AUTOSAR XML (schema 4-0-3)
package /CalibrationComponents
  parameter sw component type SOER: data-type-mapping=SOER_CodeDataTypeMappingsSet
    provide port SOER_Pport: provided-interface=SOER_if
      provided-com-specs:
        init-value=20.408000946044922, parameter=KeSOER_kE_BattRmngEnergy_MaxVal
        init-value=0, parameter=KeSOER_kE_BattRmngEnergy_minVal
        init-value=0, parameter=KeSOER_kE_OvrdValue_BattRmngEnergy
        init-value=0, parameter=KeSOER_b_OvrdCond_BattRmngEnergy
package /SOER_Code_pkg/SOER_Code_swc
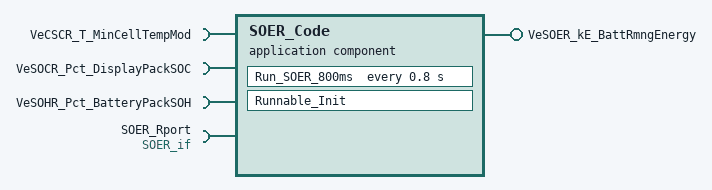
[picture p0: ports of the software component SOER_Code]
  application sw component type SOER_Code
    require port VeCSCR_T_MinCellTempMod: nonqueued-receiver-com-spec{data-element=VeCSCR_T_MinCellTempMod, init-value=0}, required-interface=VeCSCR_T_MinCellTempMod
    require port VeSOCR_Pct_DisplayPackSOC: nonqueued-receiver-com-spec{data-element=VeSOCR_Pct_DisplayPackSOC, init-value=0}, required-interface=VeSOCR_Pct_DisplayPackSOC
    require port VeSOHR_Pct_BatteryPackSOH: nonqueued-receiver-com-spec{data-element=VeSOHR_Pct_BatteryPackSOH, init-value=0}, required-interface=VeSOHR_Pct_BatteryPackSOH
    provide port VeSOER_kE_BattRmngEnergy: nonqueued-sender-com-spec{data-element=VeSOER_kE_BattRmngEnergy, init-value=0}, provided-interface=VeSOER_kE_BattRmngEnergy
    require port SOER_Rport: required-interface=SOER_if
    behavior SOER_Code: constant-value-mapping=SOER_Code_datatype_AVS_MappingSet, data-type-mapping=SOER_CodeDataTypeMappingsSet, handle-termination-and-restart=NO-SUPPORT
      static-memorys:
        data VeSOER_kE_BattRmngEnergy0: category=VALUE, sw-calibration-access=READ-ONLY, type=Float
      timing event Event_Run_SOER_800ms: start-on-event=Run_SOER_800ms, period=0.8
      runnable Runnable_Init: symbol=SOER_Code_Init
      runnable Run_SOER_800ms
        data-read-access:
          access IN_VeCSCR_T_MinCellTempMod_VeCSCR_T_MinCellTempMod: accessed-variable=VeCSCR_T_MinCellTempMod.VeCSCR_T_MinCellTempMod
          access IN_VeSOCR_Pct_DisplayPackSOC_VeSOCR_Pct_DisplayPackSOC: accessed-variable=VeSOCR_Pct_DisplayPackSOC.VeSOCR_Pct_DisplayPackSOC
          access IN_VeSOHR_Pct_BatteryPackSOH_VeSOHR_Pct_BatteryPackSOH: accessed-variable=VeSOHR_Pct_BatteryPackSOH.VeSOHR_Pct_BatteryPackSOH
        data-send-points:
          access OUT_VeSOER_kE_BattRmngEnergy_VeSOER_kE_BattRmngEnergy: accessed-variable=VeSOER_kE_BattRmngEnergy.VeSOER_kE_BattRmngEnergy
        6 x parameter access:
          CALPRM_SOER_Rport_KeSOER_b_OvrdCond_BattRmngEnergy: accessed-parameter=SOER_Rport.KeSOER_b_OvrdCond_BattRmngEnergy
          CALPRM_SOER_Rport_KeSOER_kE_BattRmngEnergy_MaxVal: accessed-parameter=SOER_Rport.KeSOER_kE_BattRmngEnergy_MaxVal
          CALPRM_SOER_Rport_KeSOER_kE_BattRmngEnergy_minVal: accessed-parameter=SOER_Rport.KeSOER_kE_BattRmngEnergy_minVal
          CALPRM_SOER_Rport_KeSOER_kE_OvrdValue_BattRmngEnergy: accessed-parameter=SOER_Rport.KeSOER_kE_OvrdValue_BattRmngEnergy
          SCALPRM_KtSOER_kE_AvailableEnergy_Table: accessed-parameter=KtSOER_kE_AvailableEnergy_Table, sw-calprm-axis-set={sw-axis-index=1, sw-axis-grouped=ar-parameter=KxSOER_kE_AvailableEnergy}
          SCALPRM_KxSOER_kE_AvailableEnergy: accessed-parameter=KxSOER_kE_AvailableEnergy, sw-calprm-axis-set=sw-axis-individual=sw-variable=VeCSCR_T_MinCellTempMod.VeCSCR_T_MinCellTempMod
      shared-parameters:
        parameter data prototype KtSOER_kE_AvailableEnergy_Table: category=CURVE, sw-calibration-access=READ-WRITE, type=Appl_KtSOER_kE_AvailableEnergy_Table, init-value=constant-reference={short-label=KtSOER_kE_AvailableEnergy_Table, constant=KtSOER_kE_AvailableEnergy_Table}
        parameter data prototype KxSOER_kE_AvailableEnergy: category=COM_AXIS, sw-calibration-access=READ-WRITE, type=Appl_KxSOER_kE_AvailableEnergy, init-value=constant-reference={short-label=KxSOER_kE_AvailableEnergy, constant=KxSOER_kE_AvailableEnergy}
